# K1921VG015 register map
Vendor: NIIET; Series: K1921Vxxx; File version: 1.12
Registers are 32-bit, read-write, reset 0x0 unless marked. A register's access mark holds for its fields unless they carry their own. Offsets are from the block's base; [hi:lo] are bit positions; lines under a group give offsets from that group; {n}, {i} and the like mark numbered series.

## PMURTC — RTC controller registers
Base 0x38011000
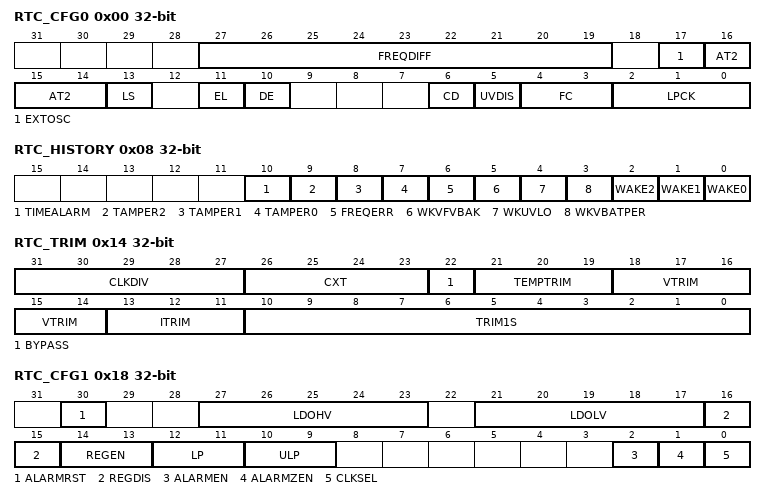
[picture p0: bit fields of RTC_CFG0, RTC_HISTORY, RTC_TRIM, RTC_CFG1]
0x00 RTC_CFG0 — Config0 register
  [27:19] FREQDIFF ro — Value of the antitamper 2 clock cycles difference relative to expected value
  [17] EXTOSC — Use external crystal oscillator and disables RC osc. (except if antitamper2 is active)
  [16:14] AT2 — 2 - AT2 disabled (default). 001 to 111 - freq limit: 4.7/7.8/10.9/14.1/17.2/20.3/23.4 [%]
    0=Disable (AT2 disabled (default)); 1=FREQ_4_7per (freq limit: 4.7%); 2=FREQ_7_8per (freq limit: 7.8%); 3=FREQ_10_9per (freq limit: 10.9%); 4=FREQ_14_1per (freq limit: 14.1%); 5=FREQ_17_2per (freq limit: 17.2%); 6=FREQ_20_3per (freq limit: 20.3%); 7=FREQ_23_4per (freq limit: 23.4%)
  [13] LS — lpclk == 1 period duration. 0 - 15 us, 1 - 30 us
  [11] EL — (must stay 0) forced enable levelshifters of LDO0
  [10] DE — clkdiv output enable (defauls is 0, output disabled)
  [6] CD — lpclk pulse disable (default is 0 - pulse enabled)
  [5] UVDIS — undervoltage disable (default is 0 - undervoltage detection enable)
  [4:3] FC — (must stay 0) force power mode of the PMU power controller submodule
    0=Def (default); 1=ForceLP (Force low power); 2=ForceHP (Force high power); 3=ForceLP2HP (Force high power from low power)
  [2:0] LPCK — defines the refresh period of comparators, in LP and ULP
0x04 RTC_TRIMRC — Trim RC OSC register
  [10:0] VAL — Trim for rc osc
0x08 RTC_HISTORY — History register
  [10] TIMEALARM ro — time alarm: time=alarm
  [9] TAMPER2 — Anti-tamper 1 detection
  [8] TAMPER1 — Anti-tamper 1 detection
  [7] TAMPER0 — Anti-tamper 0 detection
  [6] FREQERR — frequency error detection history
  [5] WKVFVBAK — when a wake event occurs, the corresponding bit is set.
  [4] WKUVLO — when a wake event occurs, the corresponding bit is set.
  [3] WKVBATPER — when a wake event occurs, the corresponding bit is set.
  [2] WAKE2 — when a wake event occurs, the corresponding bit is set.
  [1] WAKE1 — when a wake event occurs, the corresponding bit is set.
  [0] WAKE0 — when a wake event occurs, the corresponding bit is set.
0x0C RTC_TIME — Time register
  [31:0] VAL — Value of Time
0x10 RTC_ALARM — Alarm register
  [31:0] VAL — time value that will set alarm if t=1'b1
0x14 RTC_TRIM — Trim register
  [31:27] CLKDIV — division of clk32 used as anti-tamper source and output at clkdiv
  [26:23] CXT — bits reserved (must be 0 unless otherwise advised)
  [22] BYPASS — Crystal oscillator cmos bypass mode (default is 0 = disabled)
  [21:19] TEMPTRIM — temperature trim word for APC
  [18:14] VTRIM — reference voltage offset trim word for APC
  [13:11] ITRIM — bias current trim word for APC
  [10:0] TRIM1S — active oscillator (RTC_CFG0.OSCSEL) 1sec trim word (to apply each 64sec)
0x18 RTC_CFG1 — Config1 register
  [30] ALARMRST — alarm reset (resets alarm if r=1)
  [27:23] LDOHV — LDOs high voltage for low power and ultra low power. Default 011010 - 1.32V
  [21:17] LDOLV — LDOs low voltage for low power and ultra low power. Default 000101 - 0.9V
  [16:15] REGDIS — when dis[k]=1, regulator k is disabled even with alarm=1 (default is 00)
  [14:13] REGEN — when en[k]=1, regulator k is enabled even with alarm=0 (default is 00)
  [12:11] LP — when lp[k]=1, regulator k operates in low power (default is 00)
  [10:9] ULP — when ulp[k]=1, regulator k operates in ultra-low power (default is 00)
  [2] ALARMEN — enable alarm being set by time==alarm (default is 1, set possibility enabled)
  [1] ALARMZEN — if z=1, alarmz open drain output is active; if z=0 OD output is not active (default is z=1)
  [0] CLKSEL — time register clock selection (32kHz if ck=0; 1Hz if ck=1 - default)
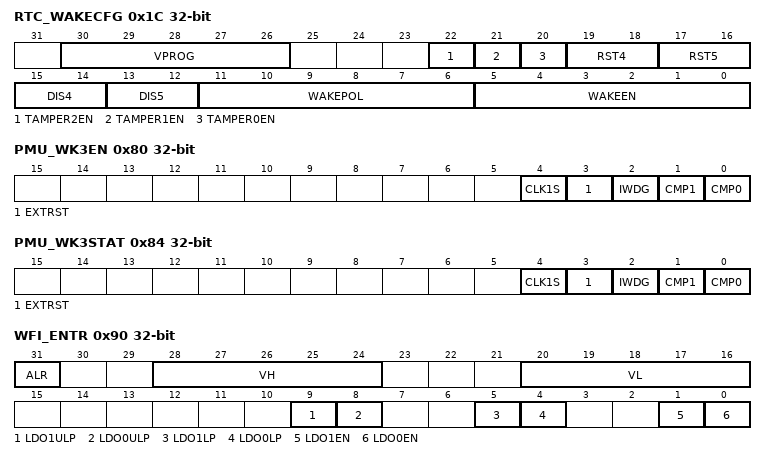
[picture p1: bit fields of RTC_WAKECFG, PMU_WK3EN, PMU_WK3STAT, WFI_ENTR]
0x1C RTC_WAKECFG — Wake config register
  [30:26] VPROG — programming voltage for high power operation of both LDOs. Default is 010100 - 1.2V
  [22] TAMPER2EN — Anti-tamper input 2 enable bit
  [21] TAMPER1EN — Anti-tamper input 1 enable bit
  [20] TAMPER0EN — Anti-tamper input 0 enable bit
  [19:18] RST4 — reset configuration for porz1 and porz0 if wake[4] occurs (default is 00)
  [17:16] RST5 — reset configuration for porz1 and porz0 if wake[5] occurs (default is 00)
  [15:14] DIS4 — values that are copied to dis[1:0] when wake[4] occurs (default is 00)
  [13:12] DIS5 — values that are copied to dis[1:0] when wake[5] occurs (default is 00)
  [11:6] WAKEPOL — if wp[i]=0, wake[i] is active high; if wp[i]=1, wake[i] is active low (default is wp[i]=0)
  [5:0] WAKEEN — crystal oscillator cmos bypass mode (default is 0 = disabled)
{0x20+4i} RTC_REG[{i}] (i=0..15) group
  0x00 RTC_REG — Register user value
    [31:0] VAL
0x60 RTC_TICKGEN wo — Tick counter register (used to generate clk1s)
  [20:0] VAL — (debug and production test only) Overwrite value of tick counter used for generation of clk1s
0x64 RTC_TRIM1S_LD wo — TRIM1S load regiter
  [31:0] VAL — RTC_TRIM.TRIM1S will be used after write to this register
0x80 PMU_WK3EN — PMU WKVBATPER Event Enable register
  [4] CLK1S — CLK1S posedge event enable for WKVBATPER
  [3] EXTRST — External reset event enable for WKVBATPER
  [2] IWDG — Independent WatchDog event enable for WKVBATPER
  [1] CMP1 — Comparator 1 event enable for WKVBATPER
  [0] CMP0 — Comparator 0 event enable for WKVBATPER
0x84 PMU_WK3STAT — PMU WKVBATPER Event Status register
  [4] CLK1S — CLK1S posedge event status for WKVBATPER
  [3] EXTRST — External reset event status for WKVBATPER
  [2] IWDG — Independent WatchDog event status for WKVBATPER
  [1] CMP1 — Comaparator 1 event status for WKVBATPER
  [0] CMP0 — Comaparator 0 event status for WKVBATPER
0x88 PMU_WCYC — PMU Wait cycles Register Access
  [7:0] VAL — Wait cycles value
0x8C WFI_PDEN — WFI Powerdown function configuration
  [0] EN — Enable powerdown function for WFI command
0x90 WFI_ENTR — WFI Powerdown Entry configuration
  [31] ALR — Automatic alarm reset RTC_CFG1.ALARMRST bit after WFI command
  [28:24] VH — Upper LDO voltage value in LP/ULP mode
  [20:16] VL — Lower LDO voltage value in LP/ULP mode
  [9] LDO1ULP — LDO1 in ultralowpower mode after WFI command
  [8] LDO0ULP — LDO0 in ultralowpower mode after WFI command
  [5] LDO1LP — LDO1 in lowpower mode after WFI command
  [4] LDO0LP — LDO0 in lowpower mode after WFI command
  [1] LDO1EN — LDO1 enabled after WFI command
  [0] LDO0EN — LDO0 enabled after WFI command
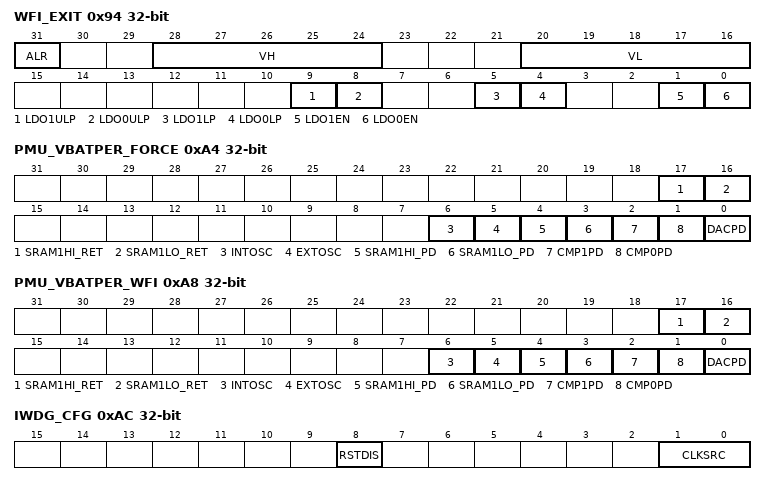
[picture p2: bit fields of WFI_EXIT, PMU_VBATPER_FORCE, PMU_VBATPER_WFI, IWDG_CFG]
0x94 WFI_EXIT — WFI Powerdown Exit configuration
  [31] ALR — Automatic alarm reset CFG1.ALARMRST bit after WFI command
  [28:24] VH — Upper LDO voltage value in LP/ULP mode
  [20:16] VL — Lower LDO voltage value in LP/ULP mode
  [9] LDO1ULP — LDO1 in ultralowpower mode after WFI command
  [8] LDO0ULP — LDO0 in ultralowpower mode after WFI command
  [5] LDO1LP — LDO1 in lowpower mode after WFI command
  [4] LDO0LP — LDO0 in lowpower mode after WFI command
  [1] LDO1EN — LDO1 enabled after WFI command
  [0] LDO0EN — LDO0 enabled after WFI command
0x98 WFI_DELENTR — WFI Delay Entering PD mode register
  [15:0] VAL — Value in ticks of REFCLK when entering powerdown mode
0x9C WFI_DELEXIT — WFI Delay Exiting PD mode register
  [15:0] VAL — Value in ticks of REFCLK when exiting powerdown mode
0xA0 PMU_IRQEVT — PMU Interrupt event flag
  [0] IRQEVT — Flag automatic sets when ALARM, Tamper, WAKE events occurs. Need to clear for resetting request for interrupt controller
0xA4 PMU_VBATPER_FORCE — PMU vbat domain periph powerdown force register
  [17] SRAM1HI_RET ro — Upper 32k SRAM1 in retention mode
  [16] SRAM1LO_RET ro — Lower 32k SRAM1 in retention mode
  [6] INTOSC — Stop clock generation of internal RC oscillator alltime
  [5] EXTOSC — Stop clock generation of external crystal oscillator alltime
  [4] SRAM1HI_PD — Upper 32k SRAM1 powerdown alltime
  [3] SRAM1LO_PD — Lower 32k SRAM1 powerdown alltime
  [2] CMP1PD — CMP1 powerdown alltime
  [1] CMP0PD — CMP0 powerdown alltime
  [0] DACPD — DAC powerdown alltime
0xA8 PMU_VBATPER_WFI — PMU vbat domain periph powerdown WFI register
  [17] SRAM1HI_RET ro — Upper 32k SRAM1 in retention mode after WFI command
  [16] SRAM1LO_RET ro — Lower 32k SRAM1 in retention mode after WFI command
  [6] INTOSC — Stop clock generation of internal RC oscillator after WFI command
  [5] EXTOSC — Stop clock generation of external crystal oscillator after WFI command
  [4] SRAM1HI_PD — Upper 32k SRAM1 powerdown after WFI command
  [3] SRAM1LO_PD — Lower 32k SRAM1 powerdown after WFI command
  [2] CMP1PD — CMP1 powerdown after WFI command
  [1] CMP0PD — CMP0 powerdown after WFI command
  [0] DACPD — DAC powerdown after WFI command
0xAC IWDG_CFG — IWDG Clock configuration register
  [8] RSTDIS — Disabling reset from IWDG timer counter
  [1:0] CLKSRC — Independent watchdog clock source control
    0=HSI (HighSpeed Internal clock (default)); 1=HSE (HighSpeed External clock source); 2=LSI (LowSpeed Internal clock)
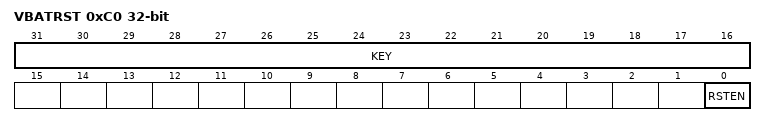
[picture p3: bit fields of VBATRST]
0xC0 VBATRST wo — VBAT Reset Register
  [31:16] KEY — KEY 'C0DE' in hexadecimal for unblocking
  [0] RSTEN — Reset enable
0xC4 CPE_STAT ro — CPE Status Register
  [0] CPE — Status of CPE PAD latched after PowerOn vbat domain
